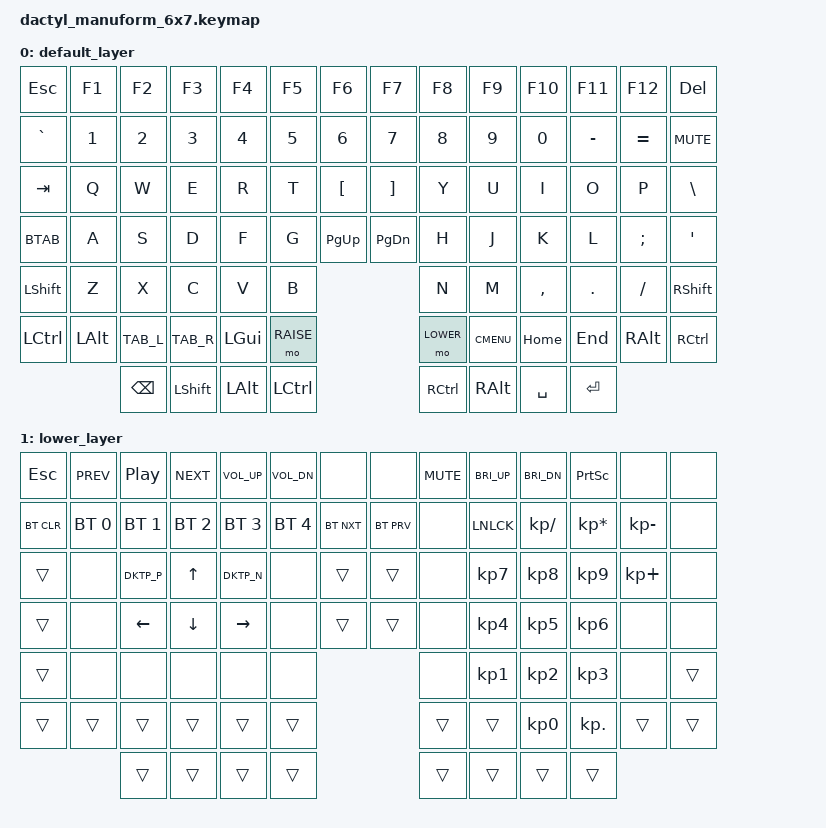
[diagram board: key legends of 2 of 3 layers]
/*
 * Copyright (c) 2020 The ZMK Contributors
 *
 * SPDX-License-Identifier: MIT
 */

#include <behaviors.dtsi>
#include <dt-bindings/zmk/keys.h>
#include <dt-bindings/zmk/bt.h>
#include <dt-bindings/zmk/outputs.h>

#define DEFAULT 0
#define LOWER   1
#define RAISE   2 

#define BTAB            LS(TAB)
#define TAB_R           LC(TAB)
#define TAB_L           LS(LC(TAB))
#define TAB_N           LC(T)
#define TAB_C           LC(W) 
#define DKTP_N          LG(LC(RIGHT))
#define DKTP_P          LG(LC(LEFT))
#define DKTP_MNG		LG(TAB)	

&caps_word {
    continue-list = <UNDERSCORE MINUS DEL BSPC LSHFT RSHFT>;
};

/ {
	keymap {
		compatible = "zmk,keymap";

		default_layer {
// .-----------------------------------------------------.                                 .----------------------------------------------------.
// | Esc   |  F1   |  F2   |  F3   |  F4  |  F5  |   F6  |                                 |  F7   |  F8  |  F9  |  F10 |  F11 |  F12  |   DEL  |
// |-------+-------+-------+-------+------+------+-------|                                 |-------+------+------+------+------+-------+--------|
// |  `    |   1   |   2   |   3   |   4  |   5  |    6  |                                 |   7   |   8  |   9  |   0  |   -  |   =   |  MUTE  |
// |-------+-------+-------+-------+------+------+-------|                                 |-------+------+------+------+------+-------+--------|
// | Tab>  |   Q   |   W   |   E   |   R  |   T  |   [{  |                                 |  ]}   |   Y  |   U  |   I  |   O  |   P   |    \   |
// |-------+-------+-------+-------+------+------+-------|                                 |-------+------+------+------+------+-------+--------|
// | <Tab  |   A   |   R   |   S   |   T  |   G  | PG_UP |                                 | PG_DN |   H  |   J  |   K  |   L  |   ;   |    '   |
// |-------+-------+-------+-------+------+------+------/                                  \------+------+------+------+------+--------+--------|
// | SHIFT |   Z   |   X   |   C   |   D  |   V  |                                                |   N  |   M  |  ,   |   .  |   /    | SHIFT  |
// |-------+-------+-------+-------+------+------/                                                \------+------+------+------+--------+--------|
// |  Ctrl |  Opt  | TAB_L | TAB_R |                                                                            | HOME |  END |   Opt  |  Ctrl  |
// '-------------------------------/-------.                                                             .------\-------------------------------'
//                                / RAISE /---------------.                              .---------------\ LOWER \  
//                               '-------/ Shift / Bkspc /                                \ Space \ Enter \-------\ 
//                              /  Win  /---------------/                                  \---------------\  Menu \
//                             '-------/  Ctrl /  Opt  /                                    \  Opt  \  Ctrl \-------'
//                                    '---------------'                                      '---------------'

			bindings = <
&kp ESC     &kp F1      &kp F2    	&kp F3    &kp F4    &kp F5    &kp F6        &kp F7      &kp F8      &kp F9      &kp F10     &kp F11     &kp F12     &kp DEL
&kp GRAVE   &kp N1      &kp N2    	&kp N3    &kp N4    &kp N5    &kp N6        &kp N7      &kp N8      &kp N9      &kp N0      &kp MINUS   &kp EQUAL   &kp C_MUTE
&kp TAB     &kp Q       &kp W     	&kp E     &kp R     &kp T     &kp LBKT      &kp RBKT    &kp Y       &kp U       &kp I       &kp O       &kp P       &kp BSLH
&kp BTAB    &kp A       &kp S     	&kp D     &kp F     &kp G     &kp PG_UP     &kp PG_DN   &kp H       &kp J       &kp K       &kp L       &kp SEMI    &kp APOS
&kp LSHFT   &kp Z       &kp X     	&kp C     &kp V     &kp B                               &kp N       &kp M       &kp COMMA   &kp DOT     &kp SLASH   &kp RSHFT
&kp LCTRL   &kp LALT    &kp TAB_L 	&kp TAB_R &kp LGUI  &mo RAISE                           &mo LOWER   &kp K_CMENU &kp HOME    &kp END     &kp RALT    &kp RCTRL
						&kp BSPC	&kp LSHFT &kp LALT 	&kp LCTRL                             &kp RCTRL   &kp RALT 	  &kp SPACE   &kp ENTER   
			>;
		};

		lower_layer {
// .-------------------------------------------------------------.                              .-------------------------------------------------------.
// | Esc      |  <<   |  play  |   >>   |  V+    |  V-   |       |                              |       |  MUTE  |  B+  |   B- | PSCRN |       |        |
// |----------+-------+--------+--------+--------+-------+-------|                              |-------+------+--------+------+-------+-------+--------|
// |  BT Clr  |  BT1  |  BT2   |   BT3  |   BT4  |  BT5  |       |                              |       |      | NUM_LK |   /  |   *   |   -   |        |
// |----------+-------+--------+--------+--------+-------+-------|                              |-------+------+--------+------+-------+-------+--------|
// |   >TAB   |       | DKTP_P |   UP   | DKTP_N |       |  [{   |                              |   }]  |      |    7   |   8  |   9   |   +   |        |
// |----------+-------+--------+--------+--------+-------+-------|                              |-------+------+--------+------+-------+-------+--------|
// |   <TAB   |       |  Left  |  Down  | Right  |       | PG_UP |                              | PG_DN |      |    4   |   5  |   6   |       |        |
// |----------+-------+--------+--------+--------+-------+-------/                              \-------+------+--------+------+-------+-------+--------|
// |  Shift   |       |        |        |  	     |       |                                              |      |    1   |   2  |   3   |       |  SHIFT |
// |----------+-------+--------+--------+--------+-------/                                              \------+--------+------+-------+-------+--------|
// |   Ctr    |  Opt  | TAB_L  | TAB_R  |                                                                               |   0  |  .    |  Opt  |  Ctrl  |
// '------------------------------------/-------.                                                               .-------\-------------------------------'
//                                     / RAISE /---------------.                                .---------------\ LOWER  \  
//                                    '-------/ Shift / Space /                                  \ Space \ Enter \--------\ 
//                                   /  Win  /---------------/                                    \---------------\  Menu  \
//                                  '-------/  Ctrl /  Opt  /                                      \  Opt  \  Ctrl \-------'
//                                         '---------------'                                        '---------------'

			bindings = <
        &kp ESC     	  &kp C_PREV  	&kp C_PP    	&kp C_NEXT	  &kp C_VOL_UP	&kp C_VOL_DN      &none                                           &none       &kp C_MUTE     &kp C_BRI_UP      	&kp C_BRI_DN			  &kp PSCRN      		  &none     	    &none
        &bt BT_CLR  	  &bt BT_SEL 0  &bt BT_SEL 1  &bt BT_SEL 2  &bt BT_SEL 3  &bt BT_SEL 4      &bt BT_NXT                                      &bt BT_PRV  &none       &kp LNLCK      	&kp KP_SLASH   	&kp KP_ASTERISK		&kp KP_MINUS   	&none       
        &trans          &none         &kp DKTP_P    &kp UP		    &kp DKTP_N	  &none             &trans                                          &trans      &none       &kp KP_N7     	&kp KP_N8      	&kp KP_N9       	&kp KP_PLUS    	&none
        &trans      		&none         &kp LEFT      &kp DOWN      &kp RIGHT     &none	            &trans                                          &trans      &none       &kp KP_N4      	&kp KP_N5      	&kp KP_N6       	&none       	  &none
        &trans          &none         &none         &none  		    &none		      &none       		    	                                                        &none       &kp KP_N1       &kp KP_N2      	&kp KP_N3         &none       	  &trans
        &trans      	  &trans        &trans        &trans        &trans        &trans                                                                        &trans      &trans          &kp KP_N0      	&kp KP_DOT			  &trans       	  &trans
                                                                  &trans        &trans            &trans      &trans                              &trans      &trans      &trans 	        &trans 
			>;
		};

		raise_layer {
// .--------------------------------------------------------.                               .---------------------------------------------------.
// |        |       |       |        |       |      |       |                               |      |      |      |      |      |       |   BLE  |
// |--------+-------+-------+--------+-------+------+-------|                               |------+------+------+------+------+-------+--------|
// |        |       |       |        |       |      |       |                               |      |      |      |      |      |       |   USB  |
// |--------+-------+-------+--------+-------+------+-------|                               |------+------+------+------+------+-------+--------|
// |        |       |       |        |       |      |       |                               |      |      |      |      |      |       |        |
// |--------+-------+-------+--------+-------+------+-------|                               |------+------+------+------+------+-------+--------|
// |        |       |       |        |       |      |       |                               |      |      |      |      |      |       |        |
// |--------+-------+-------+--------+-------+------+-------/                               \------+------+------+------+------+-------+--------|
// |        |       |       |        |       |      |                                              |      |      |      |      |       |        |
// |--------+-------+-------+--------+-------+------/                                              \------+------+------+------+-------+--------|
// |        |       |       |        |                                                                            |      |      |       |        |
// '--------------------------------/-------.                                                             .-------\------------------------------'
//                                 / RAISE /---------------.                               .---------------\ LOWER \  
//                                '-------/ Shift / Bkspc /                                 \ Space \ Enter \-------\ 
//                               /  Win  /---------------/                                   \---------------\  Menu \
//                              '-------/  Ctrl /  Opt  /                                     \  Opt  \  Ctrl \-------'
//                                     '---------------'                                       '---------------'

			bindings = <
&none &none &none  	&none  	&none  	&none   &none           &none   &none       &none       &none       &none       &none       &out OUT_BLE
&none &none &none   &none   &none   &none   &none       		&none   &none       &none       &none       &none       &none       &out OUT_USB       
&none &none &none  	&none   &none   &none   &none	       		&none	  &none       &none       &none		    &none       &none       &none
&none &none &none   &none   &none   &none   &none           &none   &none       &none       &none       &none       &none       &none
&none &none &none   &none   &none   &none   &none                   &none       &none       &none       &none       &none       &none
&none	&none	&none	  &none	  &trans  &trans 								       	  &trans      &trans      &none       &none		    &none		    &none
						&none		&none   &bootloader 		&sys_reset                         				&bootloader &sys_reset 	&none   &none   
			>;
		};
	};
};
